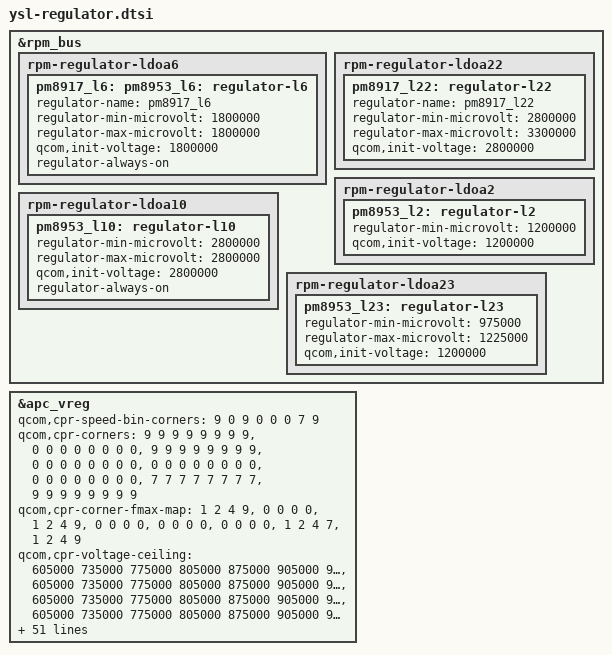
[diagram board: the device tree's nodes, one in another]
/*
 * Copyright (c) 2015-2016, The Linux Foundation. All rights reserved.
 * Copyright (C) 2019 XiaoMi, Inc.
 *
 * This program is free software; you can redistribute it and/or modify
 * it under the terms of the GNU General Public License version 2 and
 * only version 2 as published by the Free Software Foundation.
 *
 * This program is distributed in the hope that it will be useful,
 * but WITHOUT ANY WARRANTY; without even the implied warranty of
 * MERCHANTABILITY or FITNESS FOR A PARTICULAR PURPOSE.  See the
 * GNU General Public License for more details.
 */

/* msm8917-regulator */
&rpm_bus {
       rpm-regulator-ldoa6 {
		status = "okay";
		pm8917_l6: regulator-l6 {
			regulator-name = "pm8917_l6";
			regulator-min-microvolt = <1800000>;
			regulator-max-microvolt = <1800000>;
			qcom,init-voltage = <1800000>;
			status = "okay";
			regulator-always-on;
		};
	};
	
	rpm-regulator-ldoa22 {
		status = "okay";
		pm8917_l22: regulator-l22 {
			regulator-name = "pm8917_l22";
			regulator-min-microvolt = <2800000>;
			regulator-max-microvolt = <3300000>;
			qcom,init-voltage = <2800000>;
			status = "okay";
		};
	};
};

/* msm8953-regulator */
&rpm_bus {
	rpm-regulator-ldoa2 {
		pm8953_l2: regulator-l2 {
			regulator-min-microvolt = <1200000>;
			qcom,init-voltage = <1200000>;
		};
	};
	rpm-regulator-ldoa6 {
		status = "okay";
		pm8953_l6: regulator-l6 {
			regulator-min-microvolt = <1800000>;
			regulator-max-microvolt = <1800000>;
			qcom,init-voltage = <1800000>;
			status = "okay";
			regulator-always-on;
		};
	};
	rpm-regulator-ldoa10 {
		pm8953_l10: regulator-l10 {
			regulator-min-microvolt = <2800000>;
			regulator-max-microvolt = <2800000>;
			qcom,init-voltage = <2800000>;
			regulator-always-on;
		};
	};
	rpm-regulator-ldoa23 {
		pm8953_l23: regulator-l23 {
			regulator-min-microvolt = <975000>;
			regulator-max-microvolt = <1225000>;
			qcom,init-voltage = <1200000>;
		};
	};
};

&apc_vreg {
	qcom,cpr-speed-bin-corners =
		<9 0 9 0 0 0 7 9>;

	qcom,cpr-corners =
		/* Speed bin 0 */
		<9 9 9 9 9 9 9 9>,

		/* Speed bin 1 */
		<0 0 0 0 0 0 0 0>,

		/* Speed bin 2 */
		<9 9 9 9 9 9 9 9>,

		/* Speed bin 3..5 */
		<0 0 0 0 0 0 0 0>,
		<0 0 0 0 0 0 0 0>,
		<0 0 0 0 0 0 0 0>,

		/* Speed bin 6 */
		<7 7 7 7 7 7 7 7>,

		/* Speed bin 7 */
		<9 9 9 9 9 9 9 9>;

	qcom,cpr-corner-fmax-map =
		/* Speed bin 0 */
		<1 2 4 9>,

		/* Speed bin 1 */
		<0 0 0 0>,

		/* Speed bin 2 */
		<1 2 4 9>,

		/* Speed bin 3..5 */
		<0 0 0 0>,
		<0 0 0 0>,
		<0 0 0 0>,

		/* Speed bin 6 */
		<1 2 4 7>,

		/* Speed bin 7 */
		<1 2 4 9>;

	qcom,cpr-voltage-ceiling =
		/* Speed bin 0 */
		<605000  735000 775000 805000 875000
		 905000 990000 1020000 1025000>,

		/* Speed bin 2 */
		<605000  735000 775000 805000 875000
		 905000 990000 1020000 1025000>,

		/* Speed bin 6 */
		<605000  735000 775000 805000 875000
		 905000 990000>,

		/* Speed bin 7 */
		<605000  735000 775000 805000 875000
		 905000 990000 1020000 1025000>;

	qcom,cpr-voltage-floor =
		/* Speed bin 0 */
		<500000  500000 500000 500000 500000
		 500000  500000 500000 500000>,

		/* Speed bin 2 */
		<500000  500000 500000 500000 500000
		 500000  500000 500000 500000>,

		/* Speed bin 6 */
		<500000  500000 500000 500000 500000
		 500000  500000>,

		/* Speed bin 7 */
		<500000  500000 500000 500000 500000
		 500000  500000 500000 500000>;

	qcom,cpr-floor-to-ceiling-max-range =
		/* Speed bin 0; CPR rev 0..7 */
		<    0     0     0     0     0
		     0     0     0     0>,
		<50000 50000 50000 50000 50000
		 50000 50000 50000 50000>,
		<50000 50000 50000 50000 50000
		 50000 50000 50000 50000>,
		<50000 50000 50000 50000 50000
		 50000 50000 50000 50000>,
		<50000 50000 50000 50000 50000
		 50000 50000 50000 50000>,
		<50000 50000 50000 50000 50000
		 50000 50000 50000 50000>,
		<50000 50000 50000 50000 50000
		 50000 50000 50000 50000>,
		<50000 50000 50000 50000 50000
		 50000 50000 50000 50000>,

		/* Speed bin 2; CPR rev 0..7 */
		<    0     0     0     0     0
		     0     0     0     0>,
		<50000 50000 50000 50000 50000
		 50000 50000 50000 50000>,
		<50000 50000 50000 50000 50000
		 50000 50000 50000 50000>,
		<50000 50000 50000 50000 50000
		 50000 50000 50000 50000>,
		<50000 50000 50000 50000 50000
		 50000 50000 50000 50000>,
		<50000 50000 50000 50000 50000
		 50000 50000 50000 50000>,
		<50000 50000 50000 50000 50000
		 50000 50000 50000 50000>,
		<50000 50000 50000 50000 50000
		 50000 50000 50000 50000>,

		/* Speed bin 6; CPR rev 0..7 */
		<    0     0     0     0     0
		     0     0>,
		<50000 50000 50000 50000 50000
		 50000 50000>,
		<50000 50000 50000 50000 50000
		 50000 50000>,
		<50000 50000 50000 50000 50000
		 50000 50000>,
		<50000 50000 50000 50000 50000
		 50000 50000>,
		<50000 50000 50000 50000 50000
		 50000 50000>,
		<50000 50000 50000 50000 50000
		 50000 50000>,
		<50000 50000 50000 50000 50000
		 50000 50000>,

		/* Speed bin 7; CPR rev 0..7 */
		<    0     0     0     0     0
		     0     0     0     0>,
		<50000 50000 50000 50000 50000
		 50000 50000 50000 50000>,
		<50000 50000 50000 50000 50000
		 50000 50000 50000 50000>,
		<50000 50000 50000 50000 50000
		 50000 50000 50000 50000>,
		<50000 50000 50000 50000 50000
		 50000 50000 50000 50000>,
		<50000 50000 50000 50000 50000
		 50000 50000 50000 50000>,
		<50000 50000 50000 50000 50000
		 50000 50000 50000 50000>,
		<50000 50000 50000 50000 50000
		 50000 50000 50000 50000>;

	qcom,cpr-misc-fuse-voltage-adjustment =
		/* Speed bin 0; misc fuse 0..1 */
		<    0     0     0     0      0
		     0     0     0     0>,
		<    0     0 30000     0      0
		     0     0     0     0>,

		/* Speed bin 2; misc fuse 0..1 */
		<    0     0     0     0      0
		     0     0     0     0>,
		<    0     0 30000     0      0
		     0     0     0     0>,

		/* Speed bin 6; misc fuse 0..1 */
		<    0     0     0     0      0
		     0     0>,
		<    0     0 30000     0      0
		     0     0>,

		/* Speed bin 7; misc fuse 0..1 */
		<    0     0     0     0      0
		     0     0     0     0>,
		<    0     0 30000     0      0
		     0     0     0     0>;

	qcom,mem-acc-voltage =
		/* Speed bin 0 */
		<1 1 2 2 2 2 2 2 2>,

		/* Speed bin 2 */
		<1 1 2 2 2 2 2 2 2>,

		/* Speed bin 6 */
		<1 1 2 2 2 2 2>,

		/* Speed bin 7 */
		<1 1 2 2 2 2 2 2 2>;

	qcom,corner-frequencies =
		/* Speed bin 0 */
		<652800000 1036800000 1401600000
		1689600000 1804800000 1958400000
		2016000000 2150400000 2208000000>,

		/* Speed bin 2 */
		<652800000 1036800000 1401600000
		1689600000 1804800000 1958400000
		2016000000 2150400000 2208000000>,

		/* Speed bin 6 */
		<652800000 1036800000 1401600000
		1689600000 1804800000 1958400000
		2016000000>,

		/* Speed bin 7 */
		<652800000 1036800000 1401600000
		1689600000 1804800000 1958400000
		2016000000 2150400000 2208000000>;
};
